# EFR32MG24A020F1024IM48 register map
Vendor: Silicon Labs; Series: EFR32; File version: B
Registers are 32-bit, read-write, reset 0x0 unless marked. A register's access mark holds for its fields unless they carry their own. Offsets are from the block's base; [hi:lo] are bit positions; {n}, {i} and the like mark numbered series; 'fields as' and 'values as' point back to an identical list.

## RAC_S — RAC_S Registers
Base 0xA8020000
Same registers: RAC_NS 0xB8020000
0x00 IPVERSION ro reset 0x3
0x04 EN
  [0] EN — Enable peripheral clock to this module
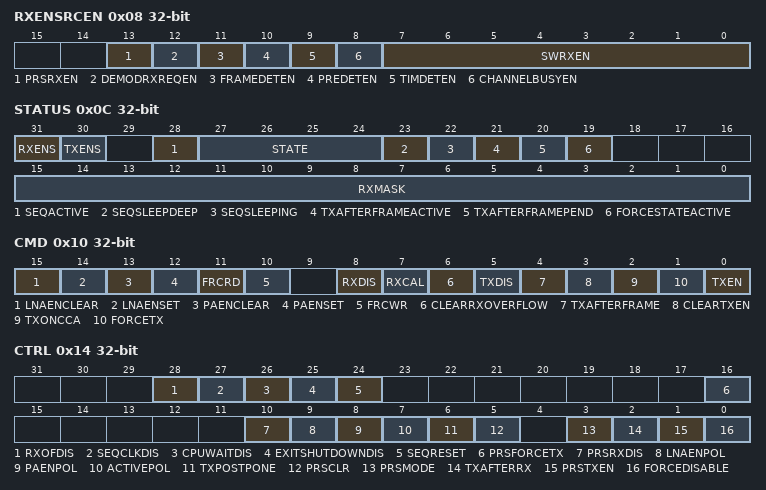
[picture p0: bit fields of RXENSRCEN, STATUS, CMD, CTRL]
0x08 RXENSRCEN
  [13] PRSRXEN — PRS RX Enable
  [12] DEMODRXREQEN — DEMOD RX Request Enable
  [11] FRAMEDETEN — Frame Detected Enable
  [10] PREDETEN — Preamble Detected Enable
  [9] TIMDETEN — Timing Detected Enable
  [8] CHANNELBUSYEN — Channel Busy Enable
  [7:0] SWRXEN — SW RX Enable
0x0C STATUS ro
  [31] RXENS — RXEN Status
    0=RXEN is not set; 1=RXEN is set
  [30] TXENS — TXEN Status
    0=TXEN is not set; 1=TXEN is set
  [28] SEQACTIVE
  [27:24] STATE — Radio State
    0=OFF (Radio is off); 1=RXWARM (Radio is enabling receiver); 2=RXSEARCH (Radio is listening for incoming frames); 3=RXFRAME (Radio is receiving a frame); 4=RXPD (Radio is powering down receiver and going to OFF state); 5=RX2RX (Radio remains in receive mode after frame reception is completed); 6=RXOVERFLOW (Received data was lost due to full receive buffer); 7=RX2TX (Radio is disabling receiver and enabling transmitter); 8=TXWARM (Radio is enabling transmitter); 9=TX (Radio is transmitting data); 10=TXPD (Radio is powering down transmitter and going to OFF state); 11=TX2RX (Radio is disabling transmitter and enabling reception); 12=TX2TX (Radio is preparing for a transmission after the previous transmission was ended); 13=SHUTDOWN (Radio is powering down receiver and going to OFF state); 14=POR (Radio power-on-reset state)
  [23] SEQSLEEPDEEP — SEQ in deep sleep
  [22] SEQSLEEPING — SEQ in sleeping
  [21] TXAFTERFRAMEACTIVE
    0=The currently ongoing TX was not initiated by a TXAFTERFRAME command; 1=The currently ongoing TX was initiated by a TXAFTERFRAME command
  [20] TXAFTERFRAMEPEND — TX After Frame Pending
    0=A transmit after frame operation is currently not pending; 1=A transmit after frame operation is currently pending
  [19] FORCESTATEACTIVE — FSM state force active
    0=No special state transition is currently in progress; 1=A forced state transition is currently in progress
  [15:0] RXMASK — Receive Enable Mask
0x10 CMD wo
  [15] LNAENCLEAR
  [14] LNAENSET
  [13] PAENCLEAR
  [12] PAENSET
  [11] FRCRD — FRC read cmd
  [10] FRCWR — FRC write cmd
  [8] RXDIS — RX Disable
  [7] RXCAL — Start an RX Calibration
  [6] CLEARRXOVERFLOW
  [5] TXDIS — TX Disable
  [4] TXAFTERFRAME
  [3] CLEARTXEN — Clear TX Enable
  [2] TXONCCA — Transmit On CCA
  [1] FORCETX — Force TX Command
  [0] TXEN — Transmitter Enable
0x14 CTRL
  [28] RXOFDIS — Switch to RXOVERFLOW Disable
  [27] SEQCLKDIS — SEQ Clk Disable
  [26] CPUWAITDIS — SEQ CPU Wait Disable
  [25] EXITSHUTDOWNDIS — Exit SHUTDOWN state Disable
  [24] SEQRESET wo
  [16] PRSFORCETX — PRS Force RX
    0=PRS will not force TX; 1=The channel selected by PRSFORCETXSEL will generate a force TX pulse
  [10] PRSRXDIS — PRS RX Disable
    0=PRS will not disable RX; 1=The channel selected by PRSRXDISSEL will generate a disable RX pulse
  [9] LNAENPOL — LNAEN signal polarity
    0=Active low; 1=Active high
  [8] PAENPOL — PAEN signal polarity
    0=Active low; 1=Active high
  [7] ACTIVEPOL — ACTIVE signal polarity
    0=Active low; 1=Active high
  [6] TXPOSTPONE
    0=In the TX state transmit data is output; 1=In the TX state an unmodulated carrier is output until this bit is cleared
  [5] PRSCLR — PRS RXEN Clear
    0=RXSEARCH (The PRS RXEN signal is cleared when the RSM state enters RXSEARCH); 1=PRSCH (The Selected PRS channel in PRSCLRSEL is used as a disable pulse)
  [3] PRSMODE — PRS RXEN Mode
    0=DIRECT (The PRS signal is used directly); 1=PULSE (The PRS signal is used as an RX enable pulse)
  [2] TXAFTERRX
    0=TX will not be started automatically; 1=A transition to TX is automatically started when a received frame is accepted by the FRC
  [1] PRSTXEN — PRS TX Enable
  [0] FORCEDISABLE — Force Radio Disable
0x18 FORCESTATE
  [3:0] FORCESTATE — Force RAC state transition
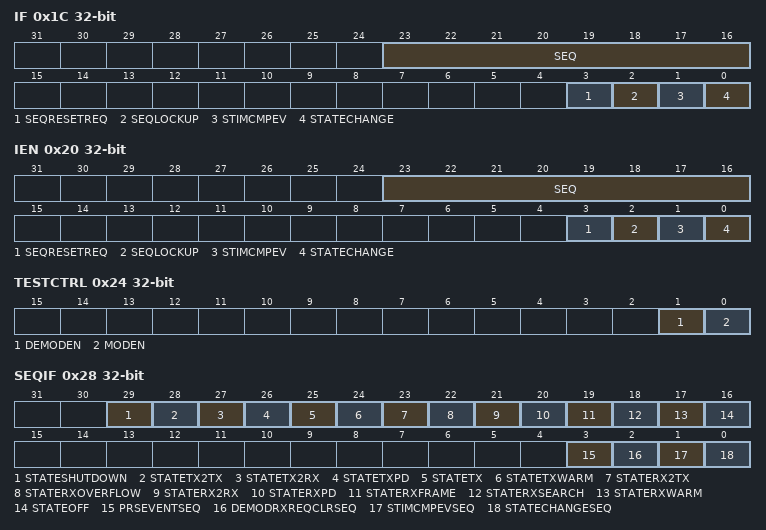
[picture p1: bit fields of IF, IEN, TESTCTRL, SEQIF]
0x1C IF
  [23:16] SEQ — Sequencer Interrupt Flags
  [3] SEQRESETREQ — SEQ reset request
  [2] SEQLOCKUP — SEQ locked up
  [1] STIMCMPEV — STIMER Compare Event
  [0] STATECHANGE — Radio State Change
0x20 IEN
  [23:16] SEQ — Sequencer Flags Interrupt Enable
  [3] SEQRESETREQ — SEQ reset request Interrupt Enable
  [2] SEQLOCKUP — SEQ locked up Interrupt Enable
  [1] STIMCMPEV — STIMER Compare Event Interrupt Enable
  [0] STATECHANGE — Radio State Change Interrupt Enable
0x24 TESTCTRL
  [1] DEMODEN — Demodulator enable
  [0] MODEN — Modulator enable
0x28 SEQIF
  [29] STATESHUTDOWN — entering STATE_SHUTDOWN
  [28] STATETX2TX — entering STATE_TX2TX
  [27] STATETX2RX — entering STATE_TX2RX
  [26] STATETXPD — entering STATE_TXPD
  [25] STATETX — entering STATE_TX
  [24] STATETXWARM — entering STATE_TXWARM
  [23] STATERX2TX — entering STATE_RX2TX
  [22] STATERXOVERFLOW — entering STATE_RXOVERFLOW
  [21] STATERX2RX — entering STATE_RX2RX
  [20] STATERXPD — entering STATE_RXPD
  [19] STATERXFRAME — entering STATE_RXFRAME
  [18] STATERXSEARCH — entering STATE_RXSEARCH
  [17] STATERXWARM — entering STATE_RXWARM
  [16] STATEOFF — entering STATE_OFF
  [3] PRSEVENTSEQ — SEQ PRS Event
  [2] DEMODRXREQCLRSEQ — Demod RX request clear
  [1] STIMCMPEVSEQ — STIMER Compare Event
  [0] STATECHANGESEQ — Radio State Change
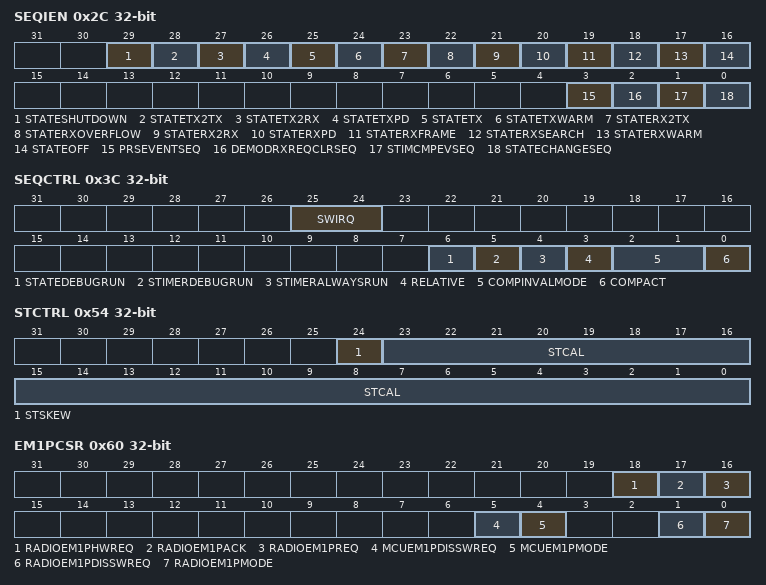
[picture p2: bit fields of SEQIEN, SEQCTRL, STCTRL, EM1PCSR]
0x2C SEQIEN
  [29] STATESHUTDOWN — STATE_SHUTDOWN Interrupt Enable
  [28] STATETX2TX — STATE_TX2TX Interrupt Enable
  [27] STATETX2RX — STATE_TX2RX Interrupt Enable
  [26] STATETXPD — STATE_TXPD Interrupt Enable
  [25] STATETX — STATE_TX Interrupt Enable
  [24] STATETXWARM — STATE_TXWARM Interrupt Enable
  [23] STATERX2TX — STATE_RX2TX Interrupt Enable
  [22] STATERXOVERFLOW — STATE_RXOVERFLOW Interrupt Enable
  [21] STATERX2RX — STATE_RX2RX Interrupt Enable
  [20] STATERXPD — STATE_RXPD Interrupt Enable
  [19] STATERXFRAME — STATE_RXFRAME Interrupt Enable
  [18] STATERXSEARCH — STATE_RXSEARC Interrupt Enable
  [17] STATERXWARM — STATE_RXWARM Interrupt Enable
  [16] STATEOFF — STATE_OFF Interrupt Enable
  [3] PRSEVENTSEQ — PRS SEQ EVENT Interrupt Enable
  [2] DEMODRXREQCLRSEQ — Demod RX req clr Interrupt Enable
  [1] STIMCMPEVSEQ — STIMER Compare Event Interrupt Enable
  [0] STATECHANGESEQ — Radio State Change Interrupt Enable
0x30 STATUS1 ro
  [7:0] TXMASK — Transmit Enable Mask
0x34 STIMER ro
  [15:0] STIMER
0x38 STIMERCOMP
  [15:0] STIMERCOMP — STIMER Compare Register
0x3C SEQCTRL
  [25:24] SWIRQ — SW spare IRQ
  [6] STATEDEBUGRUN — FSM state Debug Run
    0=FSM keeps unchanged when the Sequencer is halted; 1=FSM keeps going when the Sequencer is halted
  [5] STIMERDEBUGRUN
    0=STIMER is not running when the Sequencer is halted; 1=STIMER is running when the Sequencer is halted
  [4] STIMERALWAYSRUN
  [3] RELATIVE — STIMER Compare value relative
    0=Absolute (The compare value set for stimer is an absolute value.); 1=Relative (The compare value set for stimer is a relative value. It takes the amount of time you set to make compare event happens.)
  [2:1] COMPINVALMODE — STIMER Comp Invalid Mode
    0=NEVER (STIMERCOMP is always valid); 1=STATECHANGE (STIMERCOMP is invalidated when the RSM changes state); 2=COMPEVENT (STIMERCOMP is invalidated when an STIMER compare event occurs); 3=STATECOMP (STIMERCOMP is invalidated both when the RSM changes state and when a compare event occurs)
  [0] COMPACT — STIMER Compare Action
    0=WRAP (STIMER wraps when reaching STIMERCOMP); 1=CONTINUE (STIMER continues when reaching STIMERCOMP)
0x40 PRESC reset 0x7
  [6:0] STIMER — STIMER Prescaler
{0x44+4i} SR{i} (i=0..3)
  [31:0] SR{i} — Sequencer Storage Register {i}
0x54 STCTRL
  [24] STSKEW — Systick timer skew
  [23:0] STCAL — Systick timer freq cal
0x58 FRCTXWORD
  [7:0] WDATA — FRC write data
0x5C FRCRXWORD ro
  [7:0] RDATA — FRC read data
0x60 EM1PCSR
  [18] RADIOEM1PHWREQ ro
  [17] RADIOEM1PACK ro
  [16] RADIOEM1PREQ ro
  [5] MCUEM1PDISSWREQ
  [4] MCUEM1PMODE
    0=HWCTRL (Hardware Controls EM1P Request Signal.); 1=SWCTRL (Software Controls EM1P Request Signal)
  [1] RADIOEM1PDISSWREQ
  [0] RADIOEM1PMODE
    0=HWCTRL (Hardware Controls EM1P Request Signal); 1=SWCTRL (Software Controls EM1P Request Signal)
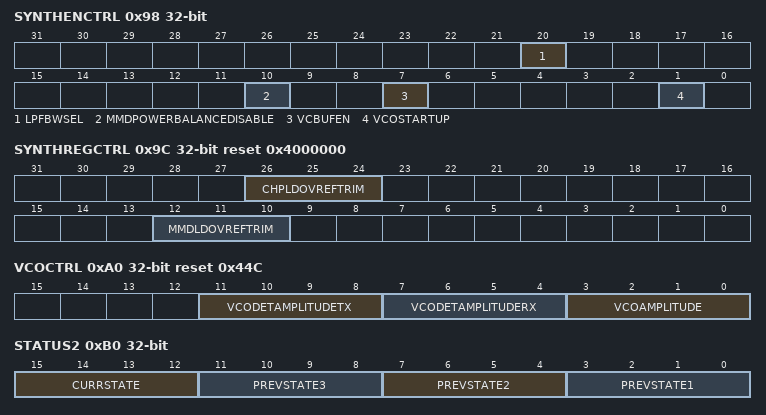
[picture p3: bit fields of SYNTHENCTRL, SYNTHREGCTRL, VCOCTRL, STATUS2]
0x98 SYNTHENCTRL
  [20] LPFBWSEL — LPF bandwidth register selection
    0=LPFBWRX (Select LPFBWRX); 1=LPFBWTX (Select LPFBWTX)
  [10] MMDPOWERBALANCEDISABLE — SYMMDPOWERBALANCEENB
    0=EnablePowerbleed; 1=DisablePowerBleed
  [7] VCBUFEN — SYLPFVCBUFEN
    0=Disabled; 1=Enabled
  [1] VCOSTARTUP — SYVCOFASTSTARTUP
    0=fast_start_up_0; 1=fast_start_up_1
0x9C SYNTHREGCTRL reset 0x4000000
  [26:24] CHPLDOVREFTRIM — SYTRIMCHPREGVREF
    0=vref0p6000; 1=vref0p6125; 2=vref0p6250; 3=vref0p6375; 4=vref0p6500; 5=vref0p6625; 6=vref0p6750; 7=vref0p6875
  [12:10] MMDLDOVREFTRIM — SYTRIMMMDREGVREF
    values as CHPLDOVREFTRIM
0xA0 VCOCTRL reset 0x44C
  [11:8] VCODETAMPLITUDETX — SYVCOAMPLPKDTX
  [7:4] VCODETAMPLITUDERX — SYVCOAMPLPKDRX
  [3:0] VCOAMPLITUDE — SYVCOAMPLOPEN
0xB0 STATUS2 ro
  [all] fields
    values as STATUS.STATE
  [15:12] CURRSTATE — Current Radio State
  [11:8] PREVSTATE3 — Previous Radio State 3
  [7:4] PREVSTATE2 — Previous Radio State 2
  [3:0] PREVSTATE1 — Previous Radio State
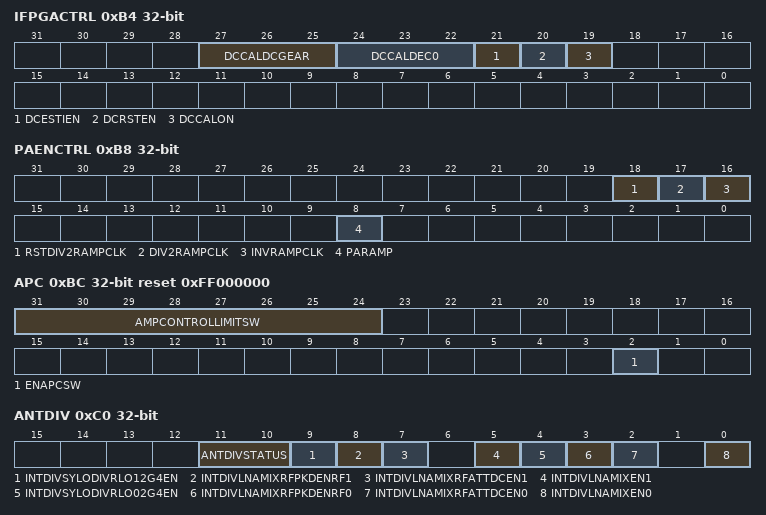
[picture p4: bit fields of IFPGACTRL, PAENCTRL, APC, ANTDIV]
0xB4 IFPGACTRL
  [27:25] DCCALDCGEAR — DC COMP GEAR Value for DCCAL
  [24:22] DCCALDEC0 — DEC0 Value for DCCAL
    0=DF3 (Decimation Factor 0 = 3. Cutoff 0.050 * f<subscript>HFXO</subscript>.); 1=DF4WIDE (Decimation Factor 0 = 4. Cutoff 0.069 * f<subscript>HFXO</subscript>.); 2=DF4NARROW (Decimation Factor 0 = 4. Cutoff 0.037 * f<subscript>HFXO</subscript>.); 3=DF8WIDE (Decimation Factor 0 = 8. Cutoff 0.012 * f<subscript>HFXO</subscript>.); 4=DF8NARROW (Decimation Factor 0 = 8. Cutoff 0.005 * f<subscript>HFXO</subscript>.)
  [21] DCESTIEN — DCESTIEN Override for RAC
    0=DISABLE (DCESTI Disabled in MODEM); 1=ENABLE (DCESTI Enabled in MODEM)
  [20] DCRSTEN — DC Compensation Filter Reset Enable
    0=DISABLE (DC Comp out of Reset); 1=ENABLE (DC Comp in Reset)
  [19] DCCALON — Enable/Disable DCCAL in DEMOD
    0=DISABLE (DC ESTI DISABLED); 1=ENABLE (DC ESTI ENABLED)
0xB8 PAENCTRL
  [18] RSTDIV2RAMPCLK — Reset Div2 PA ramping clock
  [17] DIV2RAMPCLK — Div PA ramping clock by 2
  [16] INVRAMPCLK — Invert PA ramping clock
  [8] PARAMP — PA output level ramping
0xBC APC reset 0xFF000000
  [31:24] AMPCONTROLLIMITSW — software amp_control top limit
  [2] ENAPCSW — software control bit for apc
    0=DISABLE; 1=ENABLE
0xC0 ANTDIV
  [11:10] ANTDIVSTATUS ro
    0=OFF (Both antenna disabled); 1=ANT1 (Antenna 0 enabled); 2=ANT2 (Antenna 1 enabled); 3=BOTH (Both Antenna enabled)
  [9] INTDIVSYLODIVRLO12G4EN
  [8] INTDIVLNAMIXRFPKDENRF1
  [7] INTDIVLNAMIXRFATTDCEN1
  [5] INTDIVLNAMIXEN1
  [4] INTDIVSYLODIVRLO02G4EN
  [3] INTDIVLNAMIXRFPKDENRF0
  [2] INTDIVLNAMIXRFATTDCEN0
  [0] INTDIVLNAMIXEN0
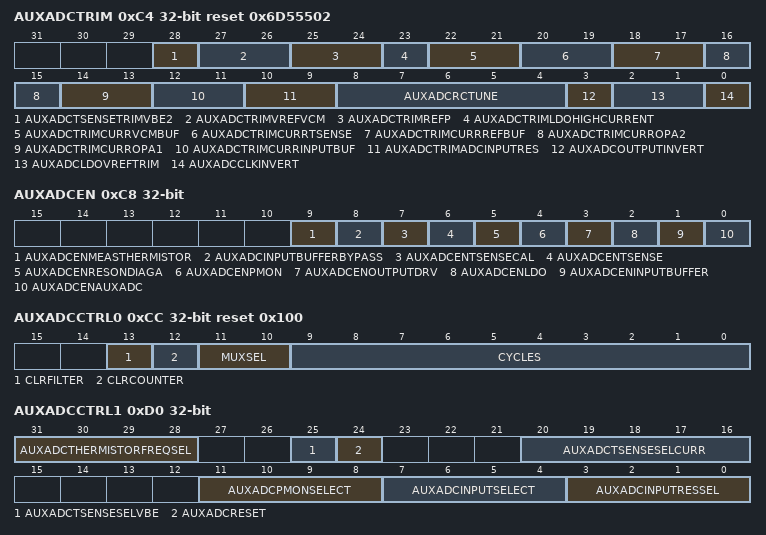
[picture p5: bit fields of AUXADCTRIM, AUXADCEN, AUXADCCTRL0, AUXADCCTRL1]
0xC4 AUXADCTRIM reset 0x6D55502
  [28] AUXADCTSENSETRIMVBE2
    0=VBE_16uA; 1=VBE_32uA
  [27:26] AUXADCTRIMVREFVCM
    0=Trim0p6; 1=Trim0p65; 2=Trim0p7; 3=Trim0p75
  [25:24] AUXADCTRIMREFP
    0=REF1p05; 1=REF1p16; 2=REF1p2; 3=REF1p25
  [23] AUXADCTRIMLDOHIGHCURRENT
    0=LowCurrentMode; 1=HighCurrentMode
  [22:21] AUXADCTRIMCURRVCMBUF
    0=Typ_minus_40pct; 1=Typ_minus_20pct; 2=Typ; 3=Typ_plus_20pct
  [20:19] AUXADCTRIMCURRTSENSE
    values as AUXADCTRIMCURRVCMBUF
  [18:17] AUXADCTRIMCURRREFBUF
    values as AUXADCTRIMCURRVCMBUF
  [16:15] AUXADCTRIMCURROPA2
    values as AUXADCTRIMCURRVCMBUF
  [14:13] AUXADCTRIMCURROPA1
    values as AUXADCTRIMCURRVCMBUF
  [12:11] AUXADCTRIMCURRINPUTBUF
    values as AUXADCTRIMCURRVCMBUF
  [10:9] AUXADCTRIMADCINPUTRES
    0=RES200k; 1=RES250k; 2=RES300k; 3=RES350k
  [8:4] AUXADCRCTUNE
  [3] AUXADCOUTPUTINVERT
    0=Disabled; 1=Enabled
  [2:1] AUXADCLDOVREFTRIM
    0=TRIM1p27; 1=TRIM1p3; 2=TRIM1p35; 3=TRIM1p4
  [0] AUXADCCLKINVERT
    0=Disable_Invert; 1=Enable_Invert
0xC8 AUXADCEN
  [9] AUXADCENMEASTHERMISTOR
    0=Disabled; 1=Enabled
  [8] AUXADCINPUTBUFFERBYPASS
    0=Not_Bypassed; 1=Bypassed
  [7] AUXADCENTSENSECAL
    0=Disabled; 1=Enabled
  [6] AUXADCENTSENSE
    0=Disabled; 1=Enabled
  [5] AUXADCENRESONDIAGA
    0=Disabled; 1=Enabled
  [4] AUXADCENPMON
    0=Disabled; 1=Enabled
  [3] AUXADCENOUTPUTDRV
    0=Disabled; 1=Enabled
  [2] AUXADCENLDO
    0=Disabled; 1=Enabled
  [1] AUXADCENINPUTBUFFER
    0=Disabled; 1=Enabled
  [0] AUXADCENAUXADC
    0=Disabled; 1=Enabled
0xCC AUXADCCTRL0 reset 0x100
  [13] CLRFILTER — Clear accumulators
  [12] CLRCOUNTER — Clear counter
  [11:10] MUXSEL — Select accumulator
  [9:0] CYCLES — Cycle number to run
0xD0 AUXADCCTRL1
  [31:28] AUXADCTHERMISTORFREQSEL
    0=DIV1; 1=DIV2; 2=DIV4; 3=DIV8; 4=DIV16; 5=DIV32; 6=DIV64; 7=DIV128; 8=DIV256; 9=DIV512; 10=DIV1024
  [25] AUXADCTSENSESELVBE
    0=VBE1; 1=VBE2
  [24] AUXADCRESET
    0=Reset_Disabled; 1=Reset_Enabled
  [20:16] AUXADCTSENSESELCURR
  [11:8] AUXADCPMONSELECT
  [7:4] AUXADCINPUTSELECT
    {v}=SEL{v} (v=0..9)
  [3:0] AUXADCINPUTRESSEL
    0=RES640kOhm; 1=RES320kOhm; 2=RES160kOhm; 3=RES80kOhm; 4=RES40kOhm; 5=RES20kOhm; 6=RES10kOhm; 7=RES5kOhm; 8=RES2p5kOhm; 9=RES1p25kOhm; 10=RES0p6kOhm; 11=RES_switch
0xD4 AUXADCOUT ro
  [27:0] AUXADCOUT — AUXADC output
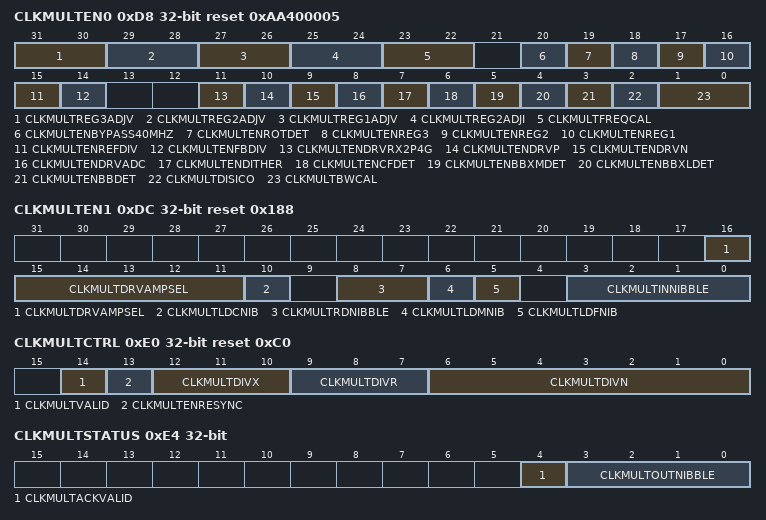
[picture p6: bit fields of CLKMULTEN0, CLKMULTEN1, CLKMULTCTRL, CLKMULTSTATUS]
0xD8 CLKMULTEN0 reset 0xAA400005
  [31:30] CLKMULTREG3ADJV
    0=v1p03; 1=v1p06; 2=v1p07; 3=v1p09
  [29:28] CLKMULTREG2ADJV
    0=v1p03; 1=v1p09; 2=v1p10; 3=v1p16
  [27:26] CLKMULTREG1ADJV
    0=v1p28; 1=v1p32; 2=v1p33; 3=v1p38
  [25:24] CLKMULTREG2ADJI
    0=I_80uA; 1=I_100uA; 2=I_120uA; 3=I_140uA
  [23:22] CLKMULTFREQCAL
    0=pedes_14uA; 1=pedes_22uA; 2=pedes_30uA; 3=pedes_38uA
  [20] CLKMULTENBYPASS40MHZ
    0=disable; 1=enable
  [19] CLKMULTENROTDET
    0=disable; 1=enable
  [18] CLKMULTENREG3
    0=disable; 1=enable
  [17] CLKMULTENREG2
    0=disable; 1=enable
  [16] CLKMULTENREG1
    0=disable; 1=enable
  [15] CLKMULTENREFDIV
    0=disable; 1=enable
  [14] CLKMULTENFBDIV
    0=disable; 1=enable
  [11] CLKMULTENDRVRX2P4G
    0=disable; 1=enable
  [10] CLKMULTENDRVP
    0=disable; 1=enable
  [9] CLKMULTENDRVN
    0=disable; 1=enable
  [8] CLKMULTENDRVADC
    0=disable; 1=enable
  [7] CLKMULTENDITHER
    0=disable; 1=enable
  [6] CLKMULTENCFDET
    0=disable; 1=enable
  [5] CLKMULTENBBXMDET
    0=disable; 1=enable
  [4] CLKMULTENBBXLDET
    0=disable; 1=enable
  [3] CLKMULTENBBDET
    0=disable; 1=enable
  [2] CLKMULTDISICO
    0=enable; 1=disable
  [1:0] CLKMULTBWCAL
    {v}=bw_{v+1}lsb (v=0..3)
0xDC CLKMULTEN1 reset 0x188
  [16:11] CLKMULTDRVAMPSEL
    0=off; 1=slide_x1; 3=slide_x2; 7=slide_x3; 15=slide_x4; 31=slide_x5; 63=slide_x6
  [10] CLKMULTLDCNIB
    0=disable; 1=enable
  [8:7] CLKMULTRDNIBBLE
    0=quarter_nibble; 1=fine_nibble; 2=moderate_nibble; 3=coarse_nibble
  [6] CLKMULTLDMNIB
    0=disable; 1=enable
  [5] CLKMULTLDFNIB
    0=disable; 1=enable
  [3:0] CLKMULTINNIBBLE
0xE0 CLKMULTCTRL reset 0xC0
  [14] CLKMULTVALID
    0=invalid; 1=valid
  [13] CLKMULTENRESYNC
    0=disable_sync; 1=enable_sync
  [12:10] CLKMULTDIVX
    0=div_1; 1=div_2; 2=div_4; 3=div_6; 4=div_8; 5=div10; 6=div12; 7=div14
  [9:7] CLKMULTDIVR
  [6:0] CLKMULTDIVN
0xE4 CLKMULTSTATUS ro
  [4] CLKMULTACKVALID
    0=invalid; 1=valid
  [3:0] CLKMULTOUTNIBBLE
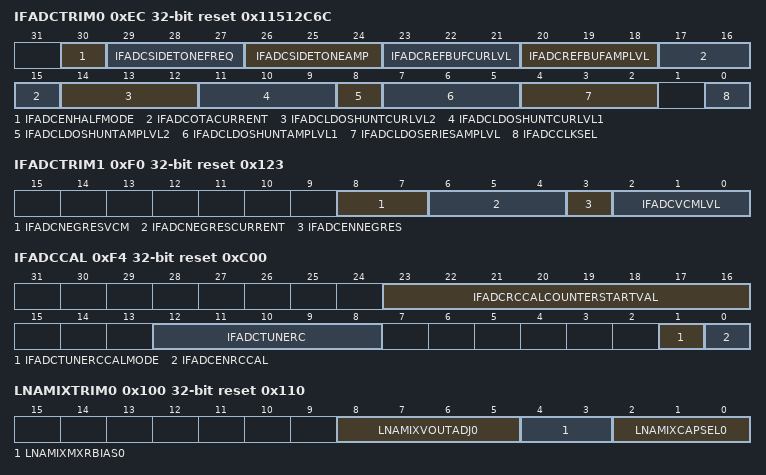
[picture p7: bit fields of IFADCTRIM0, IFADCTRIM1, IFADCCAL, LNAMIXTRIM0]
0xEC IFADCTRIM0 reset 0x11512C6C
  [30] IFADCENHALFMODE
    0=full_speed_mode; 1=half_speed_mode
  [29:27] IFADCSIDETONEFREQ
    0=na0; 1=div_128; 2=div_64; 3=div_32; 4=div_16; 5=div_8; 6=div_4; 7=na7
  [26:24] IFADCSIDETONEAMP
    0=diff_5p68mV; 1=diff_29p1mV; 2=diff_9p73mV; 3=diff_76p9mV; 4=diff_9p68_mV; 5=diff_51_mV; 6=diff_17p2_mV; 7=disable
  [23:21] IFADCREFBUFCURLVL
    0=i4u; 1=i4p5u; 2=i5u; 3=i5p5u; 4=i5u2; 5=i5p5u2; 6=i6u; 7=i6p5u
  [20:18] IFADCREFBUFAMPLVL
    0=v0p88; 1=v0p91; 2=v0p94; 3=v0p97; 4=v1p00; 5=v1p03; 6=v1p06; 7=v1p09
  [17:15] IFADCOTACURRENT
    0=i3u; 1=i3p5u; 2=i4u; 3=i4p5u; 4=i4u2; 5=i4p5u2; 6=i5u; 7=i5p5u
  [14:12] IFADCLDOSHUNTCURLVL2
    values as IFADCREFBUFCURLVL
  [11:9] IFADCLDOSHUNTCURLVL1
    0=i55u; 1=i65u; 2=i70u; 3=i85u; 4=i85u2; 5=i95u; 6=i100u; 7=i110u
  [8] IFADCLDOSHUNTAMPLVL2
    0=disable; 1=enable
  [7:5] IFADCLDOSHUNTAMPLVL1
    0=v1p125; 1=v1p150; 2=v1p175; 3=v1p200; 4=v1p225; 5=v1p250; 6=v1p275; 7=v1p300
  [4:2] IFADCLDOSERIESAMPLVL
    0=v1p225; 1=v1p250; 2=v1p275; 3=v1p300; 4=v1p325; 5=v1p350; 6=v1p375; 7=v1p400
  [0] IFADCCLKSEL
    0=clk_2p4g; 1=clk_subg
0xF0 IFADCTRIM1 reset 0x123
  [8:7] IFADCNEGRESVCM
    0=r210k_x_1uA; 1=r210k_x_1uA2; 2=r100k_x_2uA; 3=r50k_x_3uA
  [6:4] IFADCNEGRESCURRENT
    0=i1p0u; 1=i1p5u; 2=i2p0u; 3=i2p5u; 4=i2p0u2; 5=i2p5u2; 6=i3p0u; 7=i3p5u
  [3] IFADCENNEGRES
    0=disable; 1=enable
  [2:0] IFADCVCMLVL
    0=vcm_475mV; 1=vcm_500mV; 2=vcm_525mV; 3=vcm_550mV; 4=vcm_575mV; 5=vcm_600mV; 6=vcm_625mV; 7=cm_650mV
0xF4 IFADCCAL reset 0xC00
  [23:16] IFADCRCCALCOUNTERSTARTVAL
  [12:8] IFADCTUNERC
  [1] IFADCTUNERCCALMODE
    0=SYmode; 1=ADCmode
  [0] IFADCENRCCAL
    0=rccal_disable; 1=rccal_enable
0xF8 IFADCSTATUS ro
  [0] IFADCRCCALOUT
    0=lo; 1=hi
0x100 LNAMIXTRIM0 reset 0x110
  [8:5] LNAMIXVOUTADJ0
  [4:3] LNAMIXMXRBIAS0
    0=bias_1V; 2=bias_900m; 3=bias_800m
  [2:0] LNAMIXCAPSEL0
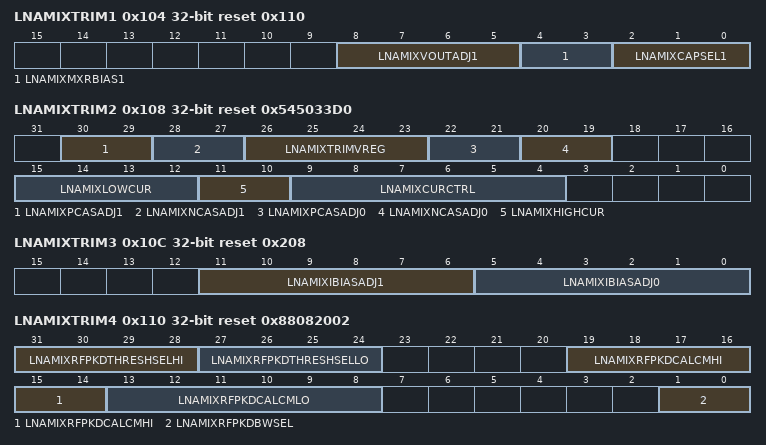
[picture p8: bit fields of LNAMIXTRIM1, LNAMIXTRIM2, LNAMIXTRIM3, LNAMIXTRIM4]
0x104 LNAMIXTRIM1 reset 0x110
  [8:5] LNAMIXVOUTADJ1
  [4:3] LNAMIXMXRBIAS1
    0=bias_1V; 2=bias_900m; 3=bias_800m
  [2:0] LNAMIXCAPSEL1
0x108 LNAMIXTRIM2 reset 0x545033D0
  [30:29] LNAMIXPCASADJ1
    0=pcas_250m; 2=pcas_300m; 3=pcas_350m
  [28:27] LNAMIXNCASADJ1
    0=ncas_1V; 2=ncas_950m; 3=ncas_900m
  [26:23] LNAMIXTRIMVREG
  [22:21] LNAMIXPCASADJ0
    0=pcas_250m; 2=pcas_300m; 3=pcas_350m
  [20:19] LNAMIXNCASADJ0
    0=ncas_1V; 2=ncas_950m; 3=ncas_900m
  [15:12] LNAMIXLOWCUR
  [11:10] LNAMIXHIGHCUR
    0=current_470uA; 1=current_530uA; 3=current_590uA
  [9:4] LNAMIXCURCTRL
0x10C LNAMIXTRIM3 reset 0x208
  [11:6] LNAMIXIBIASADJ1, [5:0] LNAMIXIBIASADJ0
0x110 LNAMIXTRIM4 reset 0x88082002
  [31:28] LNAMIXRFPKDTHRESHSELHI, [27:24] LNAMIXRFPKDTHRESHSELLO, [19:14] LNAMIXRFPKDCALCMHI, [13:8] LNAMIXRFPKDCALCMLO, [1:0] LNAMIXRFPKDBWSEL
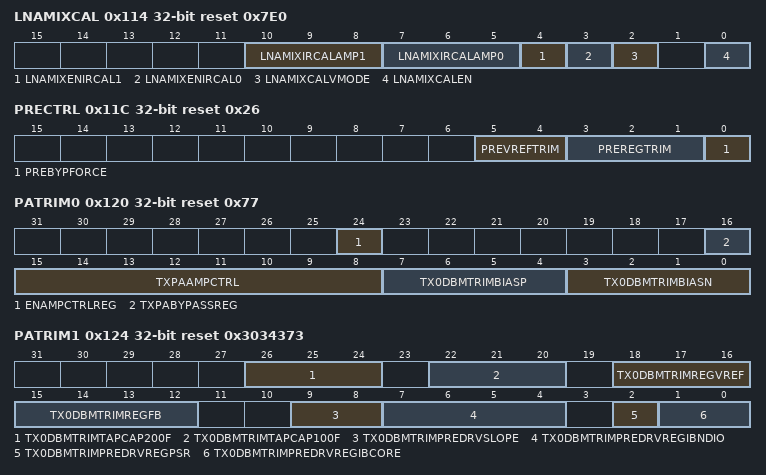
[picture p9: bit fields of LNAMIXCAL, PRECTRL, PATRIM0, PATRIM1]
0x114 LNAMIXCAL reset 0x7E0
  [10:8] LNAMIXIRCALAMP1
  [7:5] LNAMIXIRCALAMP0
  [4] LNAMIXENIRCAL1
    0=disable; 1=enable
  [3] LNAMIXENIRCAL0
    0=disable; 1=enable
  [2] LNAMIXCALVMODE
    0=current_mode; 1=voltage_mode
  [0] LNAMIXCALEN — LNAMIXCALPMOSEN
    0=cal_disable; 1=cal_enable
0x118 LNAMIXEN
  [3] LNAMIXENLDO
    0=disable; 1=enable
0x11C PRECTRL reset 0x26
  [5:4] PREVREFTRIM
    0=v0p675; 1=v0p688; 2=v0p700; 3=v0p713
  [3:1] PREREGTRIM
    0=v1p61; 1=v1p68; 2=v1p74; 3=v1p80; 4=v1p86; 5=v1p91; 6=v1p96; 7=v2p00
  [0] PREBYPFORCE
    0=not_forced; 1=forced
0x120 PATRIM0 reset 0x77
  [24] ENAMPCTRLREG
  [16] TXPABYPASSREG
    0=not_bypass; 1=bypass
  [15:8] TXPAAMPCTRL
  [7:4] TX0DBMTRIMBIASP
    0=v_1p186; 1=v_1p173; 2=v_1p16; 3=v_1p147; 4=v_1p134; 5=v_1p121; 6=v_1p108; 7=v_default_1p095; 8=v_1p083; 9=v_1p07; 10=v_1p057; 11=v_1p044; 12=v_1p031; 13=v_1p019; 14=v_1p006; 15=v_0p993
  [3:0] TX0DBMTRIMBIASN
    0=v_367m; 1=v_380m; 2=v_393m; 3=v_406m; 4=v_419m; 5=v_432m; 6=v_445m; 7=v_default_458m; 8=v_483m; 9=v_496m; 10=v_509m; 11=v_522m; 12=v_535m; 13=v_548m; 14=v_561m; 15=v_574m
0x124 PATRIM1 reset 0x3034373
  [26:24] TX0DBMTRIMTAPCAP200F
    0=Ctap_plus_0f; 1=Ctap_plus_200f; 2=Ctap_plus_400f; 3=Ctap_plus_600f; 4=Ctap_plus_800f; 5=Ctap_plus_1p; 6=Ctap_plus_1p2p; 7=Ctap_plus_1p4p
  [22:20] TX0DBMTRIMTAPCAP100F
    0=Ctap_plus_0f; 1=Ctap_plus_100f; 2=Ctap_plus_200f; 3=Ctap_plus_300f; 4=Ctap_plus_400f; 5=Ctap_plus_500f; 6=Ctap_plus_600f; 7=Ctap_plus_700f
  [18:16] TX0DBMTRIMREGVREF
    0=v_1p572; 1=v_1p593; 2=v_1p613; 3=v_default_1p634; 4=v_1p654; 5=v_1p674; 6=v_1p694; 7=v_1p714
  [15:12] TX0DBMTRIMREGFB
    0=v_1p976; 1=v_1p878; 2=v_1p788; 3=v_1p707; 4=v_default_1p633; 5=v_1p565; 6=v_1p503; 7=v_1p445; 8=v_1p392; 9=v_1p342; 10=v_1p296; 11=v_1p253; 12=v_1p213; 13=v_1p175; 14=v_1p14; 15=v_1p106
  [9:8] TX0DBMTRIMPREDRVSLOPE
    0=slope_0; 1=slope_1; 2=slope_2; 3=slope_default_max
  [7:4] TX0DBMTRIMPREDRVREGIBNDIO
    0=vreg_1p127; 1=vreg_1p171; 2=vreg_1p209; 3=vreg_1p244; 4=vreg_1p275; 5=vreg_1p305; 6=vreg_1p335; 7=vreg_default_1p362; 8=vreg_1p388; 9=vreg_1p414; 10=vreg_1p439; 11=vreg_1p463; 12=vreg_1p486; 13=vreg_1p509; 14=vreg_1p532; 15=vreg_1p555
  [2] TX0DBMTRIMPREDRVREGPSR
    0=disable; 1=enable
  [1:0] TX0DBMTRIMPREDRVREGIBCORE
    0=i_4u; 1=i_5u; 2=i_6u; 3=i_default_7u
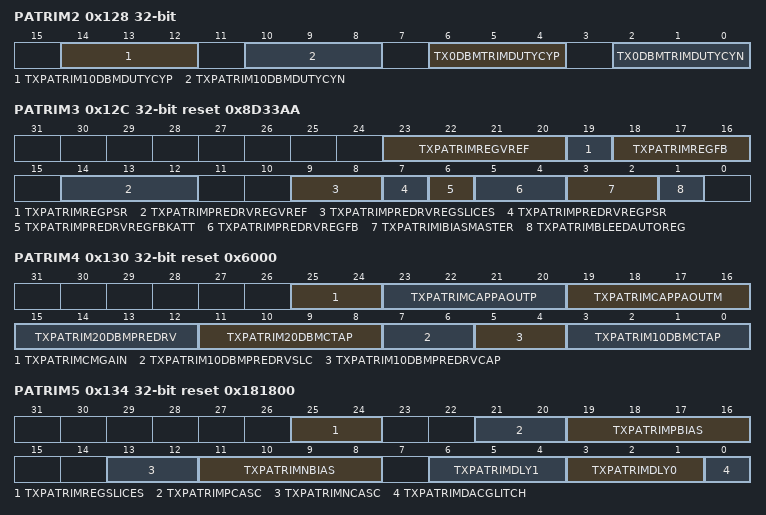
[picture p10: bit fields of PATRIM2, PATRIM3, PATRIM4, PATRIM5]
0x128 PATRIM2
  [14:12] TXPATRIM10DBMDUTYCYP
    {v}=dn_{v}pct (v=0..6); 7=na
  [10:8] TXPATRIM10DBMDUTYCYN
    {v}=up_{v}pct (v=0..6); 7=na
  [6:4] TX0DBMTRIMDUTYCYP
    {v}=dn_{v}pct (v=0..6); 7=na
  [2:0] TX0DBMTRIMDUTYCYN
    {v}=up_{v}pct (v=0..6); 7=na
0x12C PATRIM3 reset 0x8D33AA
  [23:20] TXPATRIMREGVREF
    0=vref_0p651; 1=vref_0p663; 2=vref_0p676; 3=vref_0p688; 4=vref_0p701; 5=vref_0p713; 6=vref_0p726; 7=vref_0p738; 8=vref_0p751; 9=vref_0p763; 10=vref_0p776; 11=vref_0p788; 12=vref_0p801; 13=vref_0p813; 14=vref_0p826; 15=vref_0p838
  [19] TXPATRIMREGPSR
    0=low_psr; 1=high_psr
  [18:16] TXPATRIMREGFB
    0=vreg_1p678; 1=vreg_1p735; 2=vreg_1p801; 3=vreg_1p875; 4=vreg_3p00; 5=vreg_3p14; 6=vreg_3p3; 7=vreg_3p477
  [14:12] TXPATRIMPREDRVREGVREF
    0=vref_0p675; 1=vref_0p700; 2=vref_0p725; 3=vref_0p750; 4=vref_0p775; 5=vref_0p800; 6=vref_0p825; 7=vref_0p850
  [9:8] TXPATRIMPREDRVREGSLICES
    0=iload_7p5mA; 1=iload_15mA; 2=iload_22p5mA; 3=iload_30mA
  [7] TXPATRIMPREDRVREGPSR
    0=low_psr; 1=high_psr
  [6] TXPATRIMPREDRVREGFBKATT
    0=less_bw; 1=more_bw
  [5:4] TXPATRIMPREDRVREGFB
    0=vreg_1p22; 1=vreg_1p28; 2=vreg_1p35; 3=vreg_1p44
  [3:2] TXPATRIMIBIASMASTER
    0=Ibias_is_45u; 1=Ibias_is_47p5u; 2=Ibias_is_50u; 3=Ibias_is_52p5u
  [1] TXPATRIMBLEEDAUTOREG
    0=not_automatic; 1=automatic
0x130 PATRIM4 reset 0x6000
  [25:24] TXPATRIMCMGAIN
  [23:20] TXPATRIMCAPPAOUTP
  [19:16] TXPATRIMCAPPAOUTM
  [15:12] TXPATRIM20DBMPREDRV
    0=trise_137ps; 1=trise_127ps; 2=trise_117ps; 3=trise_110ps; 4=trise_75ps; 5=trise_73ps; 6=trise_71ps; 7=trise_70ps
  [11:8] TXPATRIM20DBMCTAP
    {v}=ctap_trim_{v} (v=0..8)
  [7:6] TXPATRIM10DBMPREDRVSLC
    {v}=slc_{v} (v=0..3)
  [5:4] TXPATRIM10DBMPREDRVCAP
    {v}=cap_{v} (v=0..3)
  [3:0] TXPATRIM10DBMCTAP
    {v}=ctap_trim_{v} (v=0..8)
0x134 PATRIM5 reset 0x181800
  [25:24] TXPATRIMREGSLICES
    {v}=spare{v+1} (v=0..3)
  [21:20] TXPATRIMPCASC
    0=pcbias_n50mv; 1=pcbias_default; 2=pcbias_m50mv; 3=pcbias_m100mv
  [19:16] TXPATRIMPBIAS
    0=vpbias_up104mv; 1=vpbias_up91mv; 2=vpbias_up78mv; 3=vpbias_up65mv; 4=vpbias_up52mv; 5=vpbias_up39mv; 6=vpbias_up26mv; 7=vpbias_up13mv; 8=vpbias_default; 9=vpbias_dn13mv; 10=vpbias_dn26mv; 11=vpbias_dn38mv; 12=vpbias_dn52mv; 13=vpbias_dn65mv; 14=vpbias_dn78mv; 15=vpbias_dn91mv
  [13:12] TXPATRIMNCASC
    0=ncbias_m50mv; 1=ncbiasdefault; 2=ncbias_p50mv; 3=ncbias_p100mv
  [11:8] TXPATRIMNBIAS
    0=vnbias_dn104mv; 1=vnbias_dn91mv; 2=vnbias_dn78mv; 3=vnbias_dn65mv; 4=vnbias_dn52mv; 5=vnbias_dn39mv; 6=vnbias_dn26mv; 7=vnbias_dn13mv; 8=vnbias_default; 9=vnbias_up13mv; 10=vnbias_up26mv; 11=vnbias_up39mv; 12=vnbias_up52mv; 13=vnbias_up65mv; 14=vnbias_up78mv; 15=vnbias_up91mv
  [6:4] TXPATRIMDLY1
    0=tdly_0ps; 1=tdly_64ps; 2=tdly_65ps; 3=tdly_66ps; 4=tdly_68ps; 5=tdly_70ps; 6=tdly_75ps; 7=tdly_83ps
  [3:1] TXPATRIMDLY0
    values as TXPATRIMDLY1
  [0] TXPATRIMDACGLITCH
    0=larger_glitch; 1=smaller_glitch
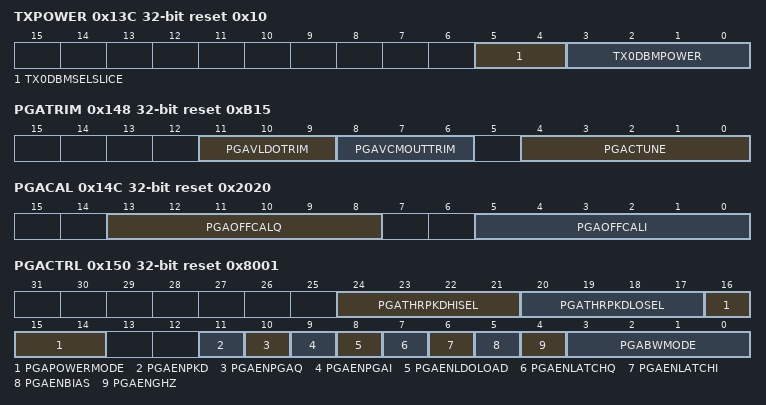
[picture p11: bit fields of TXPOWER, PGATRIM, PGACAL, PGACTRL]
0x13C TXPOWER reset 0x10
  [5:4] TX0DBMSELSLICE
    0=on_0_slice; 1=on_1_slice; 2=NA; 3=on_1_slices
  [3:0] TX0DBMPOWER
    0=on_stripe_0; 15=on_stripe_15
0x140 TXRAMP
  [0] PARAMPMODE
0x148 PGATRIM reset 0xB15
  [11:9] PGAVLDOTRIM
    0=vdda_1225; 1=vdda_1250; 2=vdda_1275; 3=vdda_1300; 4=vdda_1325; 5=vdda_1350; 6=vdda_1375; 7=vdda_1400
  [8:6] PGAVCMOUTTRIM
    0=vcm_out_475; 1=vcm_out_500; 2=vcm_out_525; 3=vcm_out_550; 4=vcm_out_575; 5=vcm_out_600; 6=vcm_out_625; 7=vcm_out_650
  [4:0] PGACTUNE
0x14C PGACAL reset 0x2020
  [13:8] PGAOFFCALQ, [5:0] PGAOFFCALI
0x150 PGACTRL reset 0x8001
  [24:21] PGATHRPKDHISEL
    0=vref50mv; 1=vref75mv; 2=vref100mv; 3=vref125mv; 4=verf150mv; 5=vref175mv; 6=vref200mv; 7=vref225mv; 8=vref250mv; 9=vref275mv; 10=vref300mv
  [20:17] PGATHRPKDLOSEL
    0=vref50mv; 1=vref75mv; 2=vref100mv; 3=vref125mv; 4=vref150mv; 5=vref175mv; 6=vref200mv; 7=vref225mv; 8=vref250mv; 9=vref275mv; 10=vref300mv
  [16:14] PGAPOWERMODE
    0=pm0_3u0; 1=pm1_3u5; 2=pm2_4u0; 3=pm3_4u5; 4=pm4_4u0; 5=pm5_4u5; 6=pm6_5u0; 7=pm7_5u5
  [11] PGAENPKD
    0=pkd_disable; 1=pkd_enable
  [10] PGAENPGAQ
    0=pgaq_disable; 1=pgaq_enable
  [9] PGAENPGAI
    0=pgai_disable; 1=pgai_enable
  [8] PGAENLDOLOAD
    0=disable_ldo_load; 1=enable_ldo_load
  [7] PGAENLATCHQ
    0=pkd_latch_q_disable; 1=pkd_latch_q_enable
  [6] PGAENLATCHI
    0=pkd_latch_i_disable; 1=pkd_latch_i_enable
  [5] PGAENBIAS
    0=bias_disable; 1=bias_enable
  [4] PGAENGHZ
    0=ghz_disable; 1=ghz_enable
  [3:0] PGABWMODE
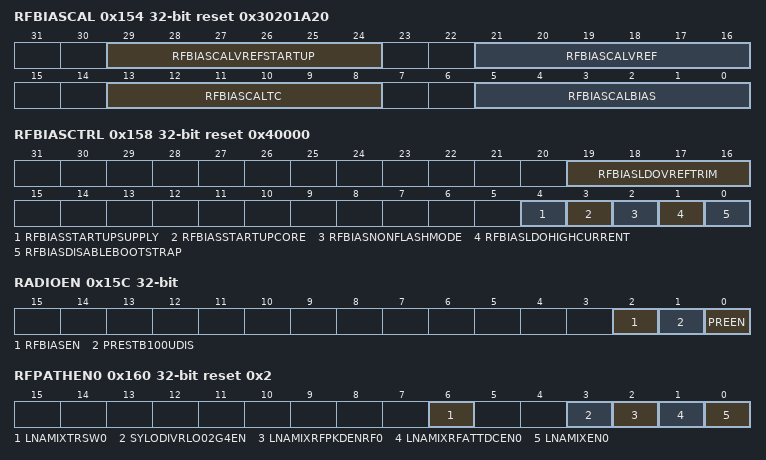
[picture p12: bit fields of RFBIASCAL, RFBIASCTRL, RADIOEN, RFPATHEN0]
0x154 RFBIASCAL reset 0x30201A20
  [29:24] RFBIASCALVREFSTARTUP, [21:16] RFBIASCALVREF, [13:8] RFBIASCALTC, [5:0] RFBIASCALBIAS
0x158 RFBIASCTRL reset 0x40000
  [19:16] RFBIASLDOVREFTRIM
    0=vref_v0p800; 1=vref_v0p813; 2=vref_v0p825; 3=vref_v0p837; 4=vref_v0p850; 5=vref_v0p863; 6=vref_v0p875; 7=vref_v0p887; 8=vref_v0p900; 9=vref_v0p913; 10=vref_v0p925; 11=vref_v0p938; 12=vref_v0p950; 13=vref_v0p963; 14=vref_v0p975; 15=vref_v0p988
  [4] RFBIASSTARTUPSUPPLY
    0=default; 1=forc_start
  [3] RFBIASSTARTUPCORE
    0=default; 1=force_start
  [2] RFBIASNONFLASHMODE
    0=flash_process; 1=non_flash_process
  [1] RFBIASLDOHIGHCURRENT
    0=low_current; 1=high_current
  [0] RFBIASDISABLEBOOTSTRAP
    0=enable_startup; 1=disable_startup
0x15C RADIOEN
  [2] RFBIASEN
    0=disable_rfis_vtr; 1=enable_rfis_vtr
  [1] PRESTB100UDIS
    0=i100ua_enabled; 1=i100ua_disabled
  [0] PREEN
    0=powered_off; 1=powered_on
0x160 RFPATHEN0 reset 0x2
  [6] LNAMIXTRSW0
    0=disabled; 1=enabled
  [3] SYLODIVRLO02G4EN
    0=disable; 1=enable
  [2] LNAMIXRFPKDENRF0
    0=disable; 1=enable_path
  [1] LNAMIXRFATTDCEN0
    0=disable_dc; 1=enable_dc
  [0] LNAMIXEN0
    0=disable; 1=enable
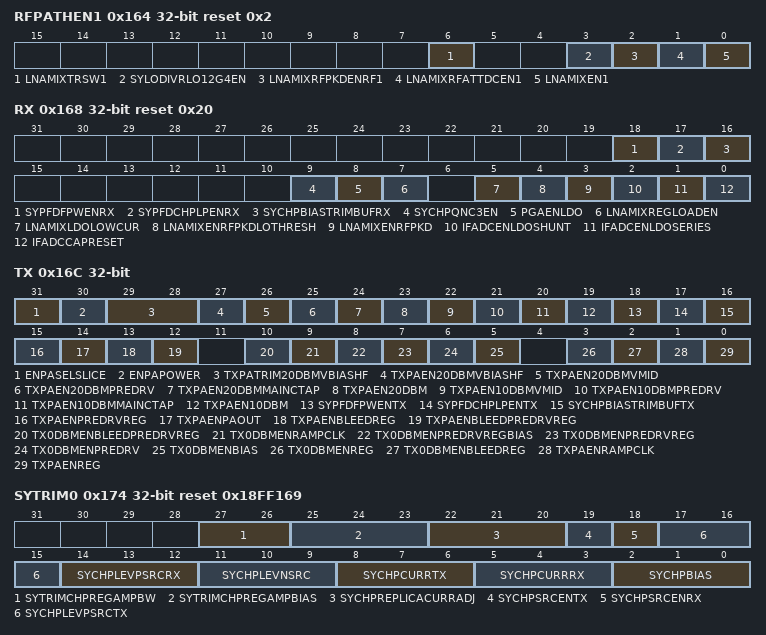
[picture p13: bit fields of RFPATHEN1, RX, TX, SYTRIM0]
0x164 RFPATHEN1 reset 0x2
  [6] LNAMIXTRSW1
    0=disabled; 1=enabled
  [3] SYLODIVRLO12G4EN
    0=disable; 1=enable
  [2] LNAMIXRFPKDENRF1
    0=disable; 1=enable_path
  [1] LNAMIXRFATTDCEN1
    0=disable_dc; 1=enable_dc
  [0] LNAMIXEN1
    0=disable; 1=enable
0x168 RX reset 0x20
  [18] SYPFDFPWENRX
    0=disable; 1=enable
  [17] SYPFDCHPLPENRX
    0=disable; 1=enable
  [16] SYCHPBIASTRIMBUFRX
    0=i_tail_10u; 1=i_tail_20u
  [9] SYCHPQNC3EN
    0=qnc_2; 1=qnc_3
  [8] PGAENLDO
    0=disable_ldo; 1=enable_ldo
  [7] LNAMIXREGLOADEN
    0=disable_resistor; 1=enable_resistor
  [5] LNAMIXLDOLOWCUR
    0=regular_mode; 1=low_current_mode
  [4] LNAMIXENRFPKDLOTHRESH
    0=disable; 1=enable
  [3] LNAMIXENRFPKD
    0=disable; 1=enable
  [2] IFADCENLDOSHUNT
    0=shunt_ldo_disable; 1=shunt_ldo_enable
  [1] IFADCENLDOSERIES
    0=series_ldo_disable; 1=series_ldo_enable
  [0] IFADCCAPRESET
    0=cap_reset_disable; 1=cap_reset_enable
0x16C TX
  [31] ENPASELSLICE — Override
  [30] ENPAPOWER — Override
  [29:28] TXPATRIM20DBMVBIASHF
    0=bias_avss; 1=bias_low; 2=bias_mid; 3=bias_high
  [27] TXPAEN20DBMVBIASHF
    0=disable_bias; 1=enable_bias
  [26] TXPAEN20DBMVMID
    0=disable; 1=enable
  [25] TXPAEN20DBMPREDRV
    0=disable; 1=enable
  [24] TXPAEN20DBMMAINCTAP
    0=ctap_main_dis; 1=ctap_main_en
  [23] TXPAEN20DBM
    0=disable; 1=enable
  [22] TXPAEN10DBMVMID
    0=disable; 1=enable
  [21] TXPAEN10DBMPREDRV
    0=disable; 1=enable
  [20] TXPAEN10DBMMAINCTAP
    0=ctap_main_dis; 1=ctap_main_en
  [19] TXPAEN10DBM
    0=disable; 1=enable
  [18] SYPFDFPWENTX
    0=disable; 1=enable
  [17] SYPFDCHPLPENTX
    0=disable; 1=enable
  [16] SYCHPBIASTRIMBUFTX
    0=i_tail_10u; 1=i_tail_20u
  [15] TXPAENPREDRVREG
    0=disable; 1=enable
  [14] TXPAENPAOUT
    0=disable; 1=enable
  [13] TXPAENBLEEDREG
    0=disable; 1=enable
  [12] TXPAENBLEEDPREDRVREG
    0=disable; 1=enable
  [10] TX0DBMENBLEEDPREDRVREG
    0=disable; 1=enable
  [9] TX0DBMENRAMPCLK
    0=disable; 1=enable
  [8] TX0DBMENPREDRVREGBIAS
    0=disable; 1=enable
  [7] TX0DBMENPREDRVREG
    0=disable; 1=enable
  [6] TX0DBMENPREDRV
    0=disable; 1=enable
  [5] TX0DBMENBIAS
    0=disable; 1=enable
  [3] TX0DBMENREG
    0=disable; 1=enable
  [2] TX0DBMENBLEEDREG
    0=disable; 1=enable
  [1] TXPAENRAMPCLK
    0=silence_clk; 1=en_clk
  [0] TXPAENREG
    0=disable; 1=enable
0x174 SYTRIM0 reset 0x18FF169
  [27:26] SYTRIMCHPREGAMPBW
    0=C_000f; 1=C_300f; 2=C_600f; 3=C_900f
  [25:23] SYTRIMCHPREGAMPBIAS
    0=bias_14uA; 1=bias_20uA; 2=bias_26uA; 3=bias_32uA; 4=bias_38uA; 5=bias_44uA; 6=bias_50uA; 7=bias_56uA
  [22:20] SYCHPREPLICACURRADJ
    0=load_8ua; 1=load_16ua; 2=load_20ua; 3=load_28ua; 4=load_24ua; 5=load_32ua; 6=load_36ua; 7=load_44ua
  [19] SYCHPSRCENTX
    0=disable; 1=enable
  [18] SYCHPSRCENRX
    0=disable; 1=enable
  [17:15] SYCHPLEVPSRCTX
    0=vsrcp_n105m; 1=vsrcp_n90m; 2=vsrcp_n75m; 3=vsrcp_n60m; 4=vsrcp_n45m; 5=vsrcp_n30m; 6=vsrcp_n15m; 7=vsrcp_n0m
  [14:12] SYCHPLEVPSRCRX
    values as SYCHPLEVPSRCTX
  [11:9] SYCHPLEVNSRC
  [8:6] SYCHPCURRTX
    0=curr_1p5uA; 1=curr_2p0uA; 2=curr_2p5uA; 3=curr_3p0uA; 4=curr_3p5uA; 5=curr_4p0uA; 6=curr_4p5uA; 7=curr_5p0uA
  [5:3] SYCHPCURRRX
    values as SYCHPCURRTX
  [2:0] SYCHPBIAS
    0=bias_0; 1=bias_1; 3=bias_2; 7=bias_3
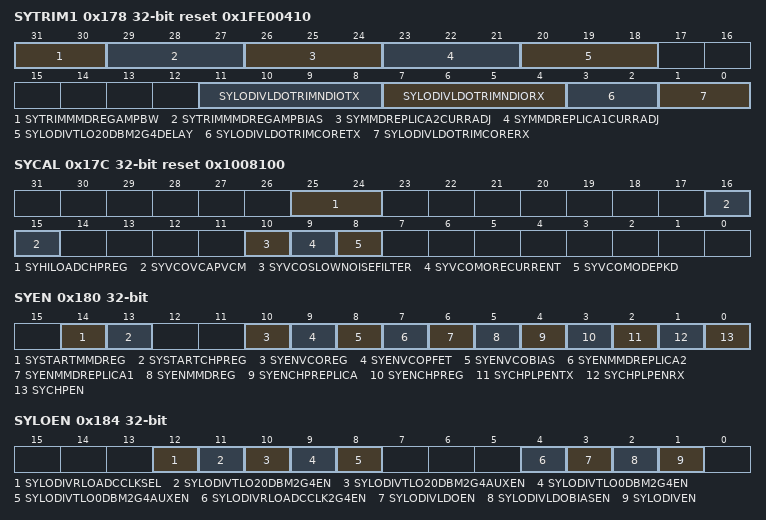
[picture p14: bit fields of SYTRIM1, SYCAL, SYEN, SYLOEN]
0x178 SYTRIM1 reset 0x1FE00410
  [31:30] SYTRIMMMDREGAMPBW
    0=C_000f; 1=C_300f; 2=C_600f; 3=C_900f
  [29:27] SYTRIMMMDREGAMPBIAS
    values as SYTRIM0.SYTRIMCHPREGAMPBIAS
  [26:24] SYMMDREPLICA2CURRADJ
    0=load_32u; 1=load_64u; 2=load_96u; 3=load_128u; 4=load_160u; 5=load_192u; 6=load_224u; 7=load_256u
  [23:21] SYMMDREPLICA1CURRADJ
    0=load_8ua; 1=load_16u; 2=load_20ua; 3=load_28ua; 4=load_24ua; 5=load_32ua; 6=load_36ua; 7=load_44ua
  [20:18] SYLODIVTLO20DBM2G4DELAY
  [11:8] SYLODIVLDOTRIMNDIOTX
    0=vreg_1p08; 1=vreg_1p11; 2=vreg_1p15; 3=vreg_1p18; 4=vreg_1p21; 5=vreg_1p24; 6=vreg_1p27; 7=vreg_1p29; 8=vreg_1p32; 9=vreg_1p34
  [7:4] SYLODIVLDOTRIMNDIORX
    values as SYLODIVLDOTRIMNDIOTX
  [3:2] SYLODIVLDOTRIMCORETX
    0=RXLO; 3=TXLO
  [1:0] SYLODIVLDOTRIMCORERX
    0=RXLO; 3=TXLO
0x17C SYCAL reset 0x1008100
  [25:24] SYHILOADCHPREG
    0=i_350uA; 1=i_500uA; 2=i_550uA; 3=i_700uA
  [16:15] SYVCOVCAPVCM
  [10] SYVCOSLOWNOISEFILTER
    0=slow_noise_filter_0; 1=slow_noise_filter_1
  [9] SYVCOMORECURRENT
    0=more_current_0; 1=more_current_1
  [8] SYVCOMODEPKD
    0=t_openloop_0; 1=t_pkdetect_1
0x180 SYEN
  [14] SYSTARTMMDREG
    0=no_fast_startup; 1=fast_startup
  [13] SYSTARTCHPREG
    0=no_fast_startup; 1=fast_startup
  [10] SYENVCOREG
    0=en_vco_reg_0; 1=en_vco_reg_1
  [9] SYENVCOPFET
    0=en_vco_pfet_0; 1=en_vco_pfet_1
  [8] SYENVCOBIAS
    0=en_vco_bias_0; 1=en_vco_bias_1
  [7] SYENMMDREPLICA2
    0=Disable; 1=Enable
  [6] SYENMMDREPLICA1
    0=disable; 1=enable
  [5] SYENMMDREG
    0=Disable; 1=Enable
  [4] SYENCHPREPLICA
    0=disable; 1=enable
  [3] SYENCHPREG
    0=Disable; 1=Enable
  [2] SYCHPLPENTX
    0=disable; 1=enable
  [1] SYCHPLPENRX
    0=disable; 1=enable
  [0] SYCHPEN
    0=disable; 1=enable
0x184 SYLOEN
  [12] SYLODIVRLOADCCLKSEL
    0=adc_clk_div8; 1=adc_clk_div16
  [11] SYLODIVTLO20DBM2G4EN
    0=disable; 1=enable
  [10] SYLODIVTLO20DBM2G4AUXEN
    0=disable; 1=enable
  [9] SYLODIVTLO0DBM2G4EN
    0=disable; 1=enable
  [8] SYLODIVTLO0DBM2G4AUXEN
    0=disable; 1=enable
  [4] SYLODIVRLOADCCLK2G4EN
    0=disable; 1=enable
  [3] SYLODIVLDOEN
    0=disable; 1=enable
  [2] SYLODIVLDOBIASEN
    0=disable; 1=enable
  [1] SYLODIVEN
    0=disable; 1=enable
0x188 SYMMDCTRL reset 0x48
  [8] SYMMDENRSDIG
    0=disable; 1=enable
  [7:5] SYMMDMODETX
    0=rx_w_swctrl; 1=rx_wo_swctrl; 2=qnc_dsm2; 3=qnc_dsm3; 4=rxlp_wo_swctrl; 5=notuse_5; 6=notuse_6; 7=notuse_7
  [4:2] SYMMDMODERX
    values as SYMMDMODETX
  [1:0] SYMMDDIVRSDIG
    0=Divideby1; 1=Divideby2; 2=Divideby4; 3=Divideby8
0x190 DIGCLKRETIMECTRL
  [10:8] DIGCLKRETIMELIMITL
  [6:4] DIGCLKRETIMELIMITH
  [2] DIGCLKRETIMERESETN
    0=reset; 1=operate
  [1] DIGCLKRETIMEDISRETIME
    0=enable_retime; 1=disable_retime
  [0] DIGCLKRETIMEENRETIME
    0=disable; 1=enable
0x194 DIGCLKRETIMESTATUS ro
  [1] DIGCLKRETIMERESETNLO
    0=lo; 1=hi
  [0] DIGCLKRETIMECLKSEL
    0=use_raw_clk; 1=use_retimed_clk
0x198 XORETIMECTRL
  [10:8] XORETIMELIMITL
  [6:4] XORETIMELIMITH
  [2] XORETIMERESETN
    0=reset; 1=operate
  [1] XORETIMEDISRETIME
    0=enable_retime; 1=disable_retime
  [0] XORETIMEENRETIME
    0=disable; 1=enable
0x19C XORETIMESTATUS ro
  [1] XORETIMERESETNLO
    0=lo; 1=hi
  [0] XORETIMECLKSEL
    0=use_raw_clk; 1=use_retimed_clk
0x1A0 AGCOVERWRITE0
  [25:24] MANIFADCSCALE — RAC Overwite PGA
  [23:20] MANPGAGAIN — RAC Overwite PGA
  [15:10] MANLNAMIXSLICE1 — RAC Overwite LNA
  [9:4] MANLNAMIXSLICE0 — RAC Overwite LNA
  [3] ENMANIFADCSCALE — Enable RAC Overwite PN
  [2] ENMANPGAGAIN — Enable RAC Overwite PGA
  [1] ENMANLNAMIXSLICE — Enable RAC Overwite LNA
  [0] ENMANLNAMIXRFATT — Enable RAC Overwite PN
0x1A4 AGCOVERWRITE1
  [29:16] MANLNAMIXRFATT1 — RAC Overwite PN
  [13:0] MANLNAMIXRFATT0 — RAC Overwite PN
0x1A8 AGCOVERWRITE2
  [15:12] MANFENOTCHCAPFINE — RAC Overwrite fenotchcapfine
  [11:8] MANFENOTCHCAPCRSE — RAC Overwrite fenotchcapcrse
  [7] MANFENOTCHRATTNENRF1 — RAC Overwrite fenotchrattnenrf1
  [6] MANFENOTCHRATTNENRF0 — RAC Overwrite fenotchrattnenrf0
  [5:2] MANFENOTCHATTNSEL — RAC Overwrite fenotchattnsel
  [1] MANFENOTCHEN — RAC Overwrite fenotchen
  [0] ENMANFENOTCH — Enable RAC Overwrite FENOTCH
0x1C8 PACTRL
  [16] TXPASLICERST
    0=disable; 1=enable
  [15:12] TXPASELSLICE
  [11] TXPASELPREDRVREGVDDRF
    0=not_selected; 1=selected
  [10] TXPASELPREDRVREGVDDPA
    0=not_selected; 1=selected
  [9] TXPALATCHBYPASS20DBM
    0=disable; 1=enable
  [8] TXPALATCHBYPASS10DBM
    0=disable; 1=enable
  [7:4] TXPAPOWER
    {v}=t{v}stripeon (v=0..15)
  [3] TXPAPULLDOWNVDDPA
    0=not_pull_down; 1=pull_down_vddpa
  [2] TXPABYPASSPREDRVREG
    0=not_bypass; 1=bypass
  [1] TX0DBMSLICERESET
    0=active; 1=reset
  [0] TX0DBMLATCHBYPASS
    0=disable; 1=enable
0x1CC FENOTCH0 reset 0x4000
  [14:12] FENOTCHVBIAS
0x1D0 FENOTCH1
  [20] FENOTCHRCCALOUT ro
  [19:16] FENOTCHRCCALOSC
  [15:8] FENOTCHRCCALCOUNTER
  [2] FENOTCHRCCALEN
    0=disable; 1=enable
  [0] FENOTCHENVDDSW
    0=disable; 1=enable
{0x3E0+4i} SCRATCH{i} (i=0..7)
0x7E8 THMSW
  [1] HALFSWITCH — Halfswitch Mode enable
    0=Disabled; 1=Enabled
  [0] EN — Enable Switch
    0=Disabled; 1=Enabled
